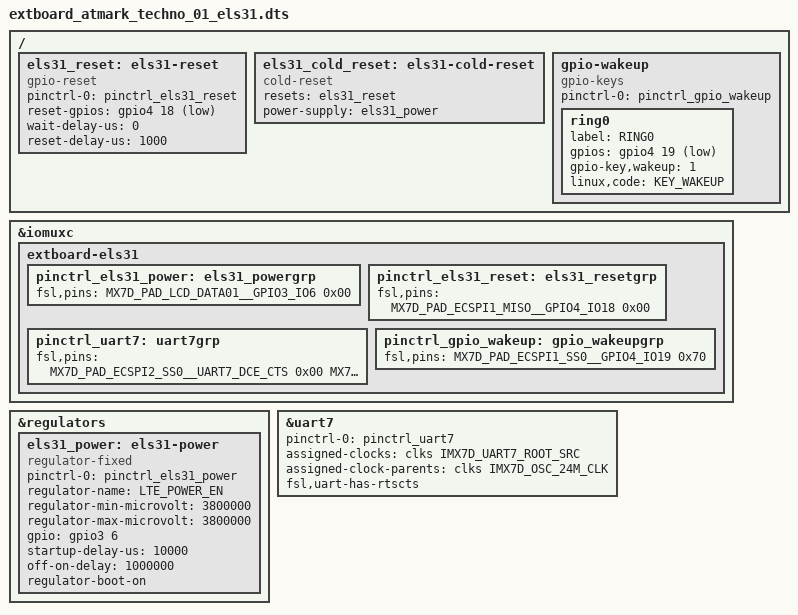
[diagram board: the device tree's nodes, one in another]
/*
 * DTS overlay for converting ti,tilcdc,slave binding to new binding.
 *
 * Copyright (C) 2018 Atmark Techno, Inc. All Rights Reserved.
 * Author: Daisuke Mizobuchi <mizo@atmark-techno.com>
 *
 * This program is free software; you can redistribute it and/or
 * modify it under the terms of the GNU General Public License
 * version 2 as published by the Free Software Foundation.
 */

#include <dt-bindings/clock/imx7d-clock.h>
#include <dt-bindings/gpio/gpio.h>
#include <dt-bindings/input/input.h>
#include "../../../../arch/arm/boot/dts/imx7d-pinfunc.h"

/dts-v1/;
/plugin/;
/ {
	fragment@0 {
		target = <&iomuxc>;
		__overlay__ {
			extboard-els31 {
				pinctrl_els31_power: els31_powergrp {
					fsl,pins = <
						MX7D_PAD_LCD_DATA01__GPIO3_IO6		0x00	/* CON7_53 */
					>;
				};

				pinctrl_els31_reset: els31_resetgrp {
					fsl,pins = <
						MX7D_PAD_ECSPI1_MISO__GPIO4_IO18	0x00	/* CON7_45 */
					>;
				};

				pinctrl_uart7: uart7grp {
					fsl,pins = <
						MX7D_PAD_ECSPI2_SS0__UART7_DCE_CTS	0x00	/* CON7_40 */
						MX7D_PAD_ECSPI2_MISO__UART7_DCE_RTS	0x10	/* CON7_41 */
						MX7D_PAD_ECSPI2_MOSI__UART7_DCE_TX	0x00	/* CON7_42 */
						MX7D_PAD_ECSPI2_SCLK__UART7_DCE_RX 	0x70	/* CON7_43 */
					>;
				};

				pinctrl_gpio_wakeup: gpio_wakeupgrp {
					fsl,pins = <
						MX7D_PAD_ECSPI1_SS0__GPIO4_IO19	0x70	/* CON7_44 */
					>;
				};
			};
		};
	};

	fragment@1 {
		target = <&regulators>;
		__overlay__ {
			els31_power: els31-power {
				compatible = "regulator-fixed";
				pinctrl-names = "default";
				pinctrl-0 = <&pinctrl_els31_power>;
				regulator-name = "LTE_POWER_EN";
				regulator-min-microvolt = <3800000>;
				regulator-max-microvolt = <3800000>;
				gpio = <&gpio3 6 GPIO_ACTIVE_HIGH>;
				startup-delay-us = <10000>;
				off-on-delay = <1000000>;
				regulator-boot-on;
			};
		};
	};

	fragment@2 {
		target-path = "/";
		__overlay__ {
			els31_reset: els31-reset {
				compatible = "gpio-reset";
				pinctrl-names = "default";
				pinctrl-0 = <&pinctrl_els31_reset>;
				reset-gpios = <&gpio4 18 GPIO_ACTIVE_LOW>;
				wait-delay-us = <0>;
				reset-delay-us = <1000>;
				#reset-cells = <0>;
			};

			els31_cold_reset: els31-cold-reset {
				compatible = "cold-reset";
				resets = <&els31_reset>;
				power-supply = <&els31_power>;
			};

			gpio-wakeup {
				compatible = "gpio-keys";
				pinctrl-names = "default";
				pinctrl-0 = <&pinctrl_gpio_wakeup>;

				ring0 {
					label = "RING0";
					gpios = <&gpio4 19 GPIO_ACTIVE_LOW>;
					gpio-key,wakeup = <1>;
					linux,code = <KEY_WAKEUP>;
				};
			};
		};
	};

	fragment@3 {
		target = <&uart7>;
		__overlay__ {
			pinctrl-names = "default";
			pinctrl-0 = <&pinctrl_uart7>;
			assigned-clocks = <&clks IMX7D_UART7_ROOT_SRC>;
			assigned-clock-parents = <&clks IMX7D_OSC_24M_CLK>;
			fsl,uart-has-rtscts;
			status = "okay";
		};
	};
};
